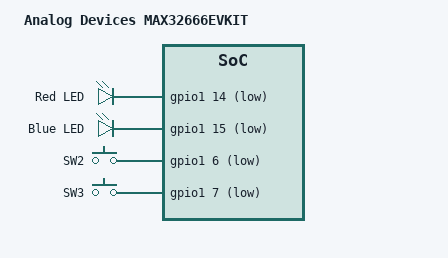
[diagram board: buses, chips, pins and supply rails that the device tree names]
/*
 * Copyright (c) 2024 Analog Devices, Inc.
 *
 * SPDX-License-Identifier: Apache-2.0
 */

/dts-v1/;

#include <adi/max32/max32666.dtsi>
#include <adi/max32/max32666-pinctrl.dtsi>
#include <zephyr/dt-bindings/gpio/adi-max32-gpio.h>
#include <zephyr/dt-bindings/input/input-event-codes.h>

/ {
	model = "Analog Devices MAX32666EVKIT";
	compatible = "adi,max32666evkit";

	leds {
		compatible = "gpio-leds";

		led1: led_1 {
			gpios = <&gpio1 14 (GPIO_ACTIVE_LOW | MAX32_GPIO_VSEL_VDDIOH)>;
			label = "Red LED";
		};

		led2: led_2 {
			gpios = <&gpio1 15 (GPIO_ACTIVE_LOW | MAX32_GPIO_VSEL_VDDIOH)>;
			label = "Blue LED";
		};
	};

	buttons {
		compatible = "gpio-keys";

		pb1: pb1 {
			gpios = <&gpio1 6
				 (GPIO_PULL_UP | GPIO_ACTIVE_LOW | MAX32_GPIO_VSEL_VDDIOH)>;
			label = "SW2";
			zephyr,code = <INPUT_KEY_0>;
		};

		pb2: pb2 {
			gpios = <&gpio1 7
				 (GPIO_PULL_UP | GPIO_ACTIVE_LOW | MAX32_GPIO_VSEL_VDDIOH)>;
			label = "SW3";
			zephyr,code = <INPUT_KEY_1>;
		};
	};

	spibb0: spibb0 {
		compatible = "zephyr,spi-bitbang";
		status = "disabled";
		#address-cells = <1>;
		#size-cells = <0>;
		clk-gpios = <&gpio1 11 (GPIO_ACTIVE_HIGH | MAX32_GPIO_VSEL_VDDIOH)>;
		mosi-gpios = <&gpio1 9 (GPIO_ACTIVE_HIGH | MAX32_GPIO_VSEL_VDDIOH)>;
		cs-gpios = <&gpio1 8 (GPIO_ACTIVE_HIGH | MAX32_GPIO_VSEL_VDDIOH)>;

		ls0xx_ls013b7dh03: ls0xx@0 {
			compatible = "sharp,ls0xx";
			status = "disabled";
			spi-max-frequency = <2000000>;
			reg = <0>;
			width = <128>;
			height = <128>;
			disp-en-gpios = <&gpio1 10 (GPIO_ACTIVE_HIGH | MAX32_GPIO_VSEL_VDDIOH)>;
		};
	};
};

&gpio0 {
	status = "okay";
};

&gpio1 {
	status = "okay";
};
